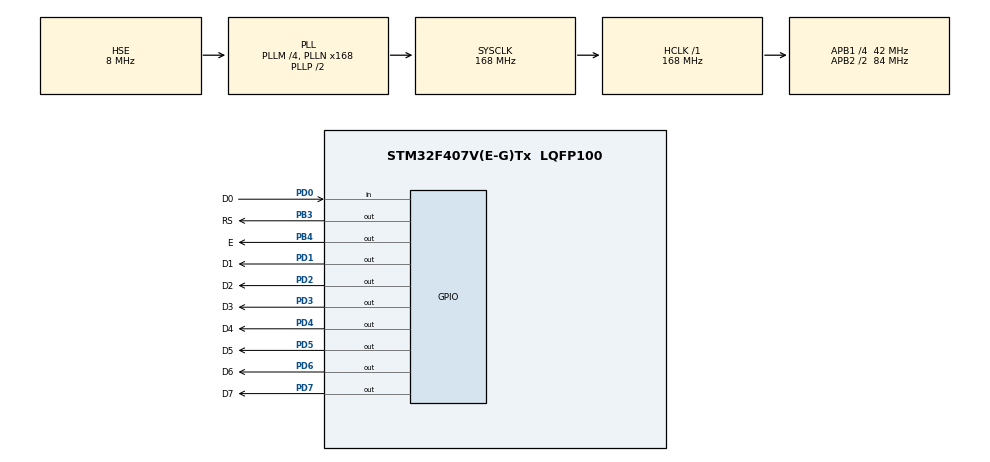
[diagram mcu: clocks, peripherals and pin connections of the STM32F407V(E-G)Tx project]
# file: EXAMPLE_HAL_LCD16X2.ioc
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Mcu.Family=STM32F4
Mcu.Name=STM32F407V(E-G)Tx
Mcu.Package=LQFP100
NVIC.PriorityGroup=NVIC_PRIORITYGROUP_4
PB3.GPIO_Label=RS
PB3.Signal=GPIO_Output
PB4.GPIO_Label=E
PB4.Signal=GPIO_Output
PD0.GPIO_Label=D0
PD0.Signal=GPIO_Input
PD1.GPIO_Label=D1
PD1.Signal=GPIO_Output
PD2.GPIO_Label=D2
PD2.GPIO_Speed=GPIO_SPEED_FREQ_MEDIUM
PD2.Signal=GPIO_Output
PD3.GPIO_Label=D3
PD3.GPIO_Speed=GPIO_SPEED_FREQ_MEDIUM
PD3.Signal=GPIO_Output
PD4.GPIO_Label=D4
PD4.GPIO_Speed=GPIO_SPEED_FREQ_MEDIUM
PD4.Signal=GPIO_Output
PD5.GPIO_Label=D5
PD5.GPIO_Speed=GPIO_SPEED_FREQ_MEDIUM
PD5.Signal=GPIO_Output
PD6.GPIO_Label=D6
PD6.GPIO_Speed=GPIO_SPEED_FREQ_MEDIUM
PD6.Signal=GPIO_Output
PD7.GPIO_Label=D7
PD7.GPIO_Speed=GPIO_SPEED_FREQ_MEDIUM
PD7.Signal=GPIO_Output
PH0-OSC_IN.Mode=HSE-External-Oscillator
PH0-OSC_IN.Signal=RCC_OSC_IN
PH1-OSC_OUT.Mode=HSE-External-Oscillator
PH1-OSC_OUT.Signal=RCC_OSC_OUT
ProjectManager.HeapSize=0x200
ProjectManager.StackSize=0x400
ProjectManager.TargetToolchain=STM32CubeIDE
RCC.48MHZClocksFreq_Value=84000000
RCC.AHBFreq_Value=168000000
RCC.APB1CLKDivider=RCC_HCLK_DIV4
RCC.APB1Freq_Value=42000000
RCC.APB1TimFreq_Value=84000000
RCC.APB2CLKDivider=RCC_HCLK_DIV2
RCC.APB2Freq_Value=84000000
RCC.APB2TimFreq_Value=168000000
RCC.CortexFreq_Value=168000000
RCC.HCLKFreq_Value=168000000
RCC.HSE_VALUE=8000000
RCC.HSI_VALUE=16000000
RCC.LSE_VALUE=32768
RCC.PLLM=4
RCC.PLLN=168
RCC.PLLSourceVirtual=RCC_PLLSOURCE_HSE
RCC.SYSCLKFreq_VALUE=168000000
RCC.SYSCLKSource=RCC_SYSCLKSOURCE_PLLCLK
RCC.VCOOutputFreq_Value=336000000
board=custom

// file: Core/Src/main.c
/* USER CODE BEGIN Header */
/**
  ******************************************************************************
  * @file           : main.c
  * @brief          : Main program body
  ******************************************************************************
  ******************************************************************************
  */
/* USER CODE END Header */
#include "main.h"

/* USER CODE BEGIN Includes */
#include "STM_MY_LCD16X2.h"
/* USER CODE END Includes */

void SystemClock_Config(void);
static void MX_GPIO_Init(void);

int main(void)
{

  /* MCU Configuration--------------------------------------------------------*/

  /* Reset of all peripherals, Initializes the Flash interface and the Systick. */
  HAL_Init();

  /* Configure the system clock */
  SystemClock_Config();

  /* Initialize all configured peripherals */
  MX_GPIO_Init();

  /* Infinite loop */
  while (1)
  {

    /* USER CODE BEGIN 3 */
	  lcd16x2_init_4bits(RS_GPIO_Port, RS_Pin, E_Pin,
	//      D0_GPIO_Port, D0_Pin, D1_Pin, D2_Pin, D3_Pin,
	      D4_GPIO_Port, D4_Pin, D5_Pin, D6_Pin, D7_Pin);

	  lcd16x2_printf("Hello World");
	  HAL_Delay(1000);

    lcd16x2_1stLine();
    lcd16x2_printf("Temperature 4bits");
    HAL_Delay(1000);
    lcd16x2_2ndLine();
    lcd16x2_printf("%.2f C", 25.7824);
    HAL_Delay(1000);
    lcd16x2_clear();
    HAL_Delay(500);
  }
  /* USER CODE END 3 */
}

void SystemClock_Config(void)
{
  RCC_OscInitTypeDef RCC_OscInitStruct = {0};
  RCC_ClkInitTypeDef RCC_ClkInitStruct = {0};

  /** Configure the main internal regulator output voltage
  */
  __HAL_RCC_PWR_CLK_ENABLE();
  __HAL_PWR_VOLTAGESCALING_CONFIG(PWR_REGULATOR_VOLTAGE_SCALE1);
  /** Initializes the RCC Oscillators according to the specified parameters
  * in the RCC_OscInitTypeDef structure.
  */
  RCC_OscInitStruct.OscillatorType = RCC_OSCILLATORTYPE_HSE;
  RCC_OscInitStruct.HSEState = RCC_HSE_ON;
  RCC_OscInitStruct.PLL.PLLState = RCC_PLL_ON;
  RCC_OscInitStruct.PLL.PLLSource = RCC_PLLSOURCE_HSE;
  RCC_OscInitStruct.PLL.PLLM = 4;
  RCC_OscInitStruct.PLL.PLLN = 168;
  RCC_OscInitStruct.PLL.PLLP = RCC_PLLP_DIV2;
  RCC_OscInitStruct.PLL.PLLQ = 4;
  if (HAL_RCC_OscConfig(&RCC_OscInitStruct) != HAL_OK)
  {
    Error_Handler();
  }
  /** Initializes the CPU, AHB and APB buses clocks
  */
  RCC_ClkInitStruct.ClockType = RCC_CLOCKTYPE_HCLK|RCC_CLOCKTYPE_SYSCLK
                              |RCC_CLOCKTYPE_PCLK1|RCC_CLOCKTYPE_PCLK2;
  RCC_ClkInitStruct.SYSCLKSource = RCC_SYSCLKSOURCE_PLLCLK;
  RCC_ClkInitStruct.AHBCLKDivider = RCC_SYSCLK_DIV1;
  RCC_ClkInitStruct.APB1CLKDivider = RCC_HCLK_DIV4;
  RCC_ClkInitStruct.APB2CLKDivider = RCC_HCLK_DIV2;

  if (HAL_RCC_ClockConfig(&RCC_ClkInitStruct, FLASH_LATENCY_5) != HAL_OK)
  {
    Error_Handler();
  }
}

static void MX_GPIO_Init(void)
{
  GPIO_InitTypeDef GPIO_InitStruct = {0};

  /* GPIO Ports Clock Enable */
  __HAL_RCC_GPIOH_CLK_ENABLE();
  __HAL_RCC_GPIOD_CLK_ENABLE();
  __HAL_RCC_GPIOB_CLK_ENABLE();

  /*Configure GPIO pin Output Level */
  HAL_GPIO_WritePin(GPIOD, D1_Pin|D2_Pin|D3_Pin|D4_Pin
                          |D5_Pin|D6_Pin|D7_Pin, GPIO_PIN_RESET);

  /*Configure GPIO pin Output Level */
  HAL_GPIO_WritePin(GPIOB, RS_Pin|E_Pin, GPIO_PIN_RESET);

  /*Configure GPIO pin : D0_Pin */
  GPIO_InitStruct.Pin = D0_Pin;
  GPIO_InitStruct.Mode = GPIO_MODE_INPUT;
  GPIO_InitStruct.Pull = GPIO_NOPULL;
  HAL_GPIO_Init(D0_GPIO_Port, &GPIO_InitStruct);

  /*Configure GPIO pin : D1_Pin */
  GPIO_InitStruct.Pin = D1_Pin;
  GPIO_InitStruct.Mode = GPIO_MODE_OUTPUT_PP;
  GPIO_InitStruct.Pull = GPIO_NOPULL;
  GPIO_InitStruct.Speed = GPIO_SPEED_FREQ_LOW;
  HAL_GPIO_Init(D1_GPIO_Port, &GPIO_InitStruct);

  /*Configure GPIO pins : D2_Pin D3_Pin D4_Pin D5_Pin
                           D6_Pin D7_Pin */
  GPIO_InitStruct.Pin = D2_Pin|D3_Pin|D4_Pin|D5_Pin
                          |D6_Pin|D7_Pin;
  GPIO_InitStruct.Mode = GPIO_MODE_OUTPUT_PP;
  GPIO_InitStruct.Pull = GPIO_NOPULL;
  GPIO_InitStruct.Speed = GPIO_SPEED_FREQ_MEDIUM;
  HAL_GPIO_Init(GPIOD, &GPIO_InitStruct);

  /*Configure GPIO pins : RS_Pin E_Pin */
  GPIO_InitStruct.Pin = RS_Pin|E_Pin;
  GPIO_InitStruct.Mode = GPIO_MODE_OUTPUT_PP;
  GPIO_InitStruct.Pull = GPIO_NOPULL;
  GPIO_InitStruct.Speed = GPIO_SPEED_FREQ_LOW;
  HAL_GPIO_Init(GPIOB, &GPIO_InitStruct);

}

void Error_Handler(void)
{
  __disable_irq();
  while (1)
  {
  }
}

/************************ (C) COPYRIGHT STMicroelectronics *****END OF FILE****/
